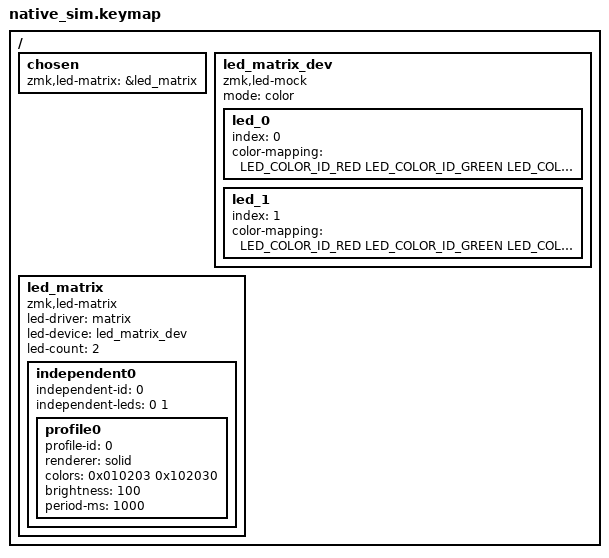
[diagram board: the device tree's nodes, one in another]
#include "../behavior_keymap.dtsi"

/ {
    chosen {
        zmk,led-matrix = &led_matrix;
    };

    led_matrix_dev: led_matrix_dev {
        compatible = "zmk,led-mock";
        mode = "color";

        led_0 { index = <0>; color-mapping = <LED_COLOR_ID_RED LED_COLOR_ID_GREEN LED_COLOR_ID_BLUE>; };
        led_1 { index = <1>; color-mapping = <LED_COLOR_ID_RED LED_COLOR_ID_GREEN LED_COLOR_ID_BLUE>; };
    };

    led_matrix: led_matrix {
        compatible = "zmk,led-matrix";
        led-driver = "matrix";
        led-device = <&led_matrix_dev>;
        led-count = <2>;

        independent0 {
            independent-id = <0>;
            independent-leds = <0 1>;

            profile0 {
                profile-id = <0>;
                renderer = "solid";
                colors = <0x010203 0x102030>;
                brightness = <100>;
                period-ms = <1000>;
            };
        };
    };
};
